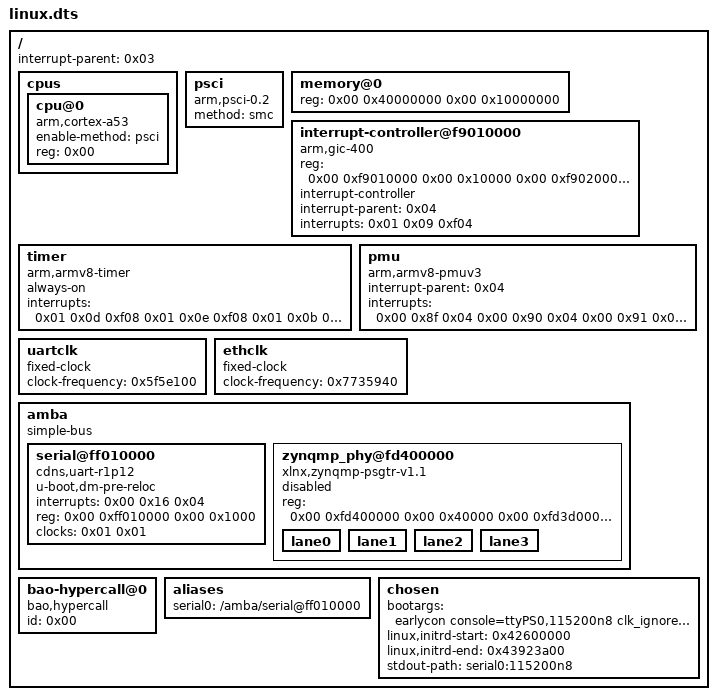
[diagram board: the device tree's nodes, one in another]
/dts-v1/;

/ {
	#address-cells = <0x02>;
	#size-cells = <0x02>;
	interrupt-parent = <0x03>;

	cpus {
		#size-cells = <0x00>;
		#address-cells = <0x01>;

		cpu@0 {
			compatible = "arm,cortex-a53\0arm,armv8";
			device_type = "cpu";
			enable-method = "psci";
			reg = <0x00>;
		};
	};

	psci {
		compatible = "arm,psci-0.2";
		method = "smc";
	};

	memory@0 {
		device_type = "memory";
		reg = <0x00 0x40000000 0x00 0x10000000>;
	};

	interrupt-controller@f9010000 {
		compatible = "arm,gic-400\0arm,cortex-a15-gic";
		#interrupt-cells = <0x03>;
		reg = <0x00 0xf9010000 0x00 0x10000 0x00 0xf9020000 0x00 0x20000 0x00 0xf9040000 0x00 0x20000 0x00 0xf9060000 0x00 0x20000>;
		interrupt-controller;
		interrupt-parent = <0x04>;
		interrupts = <0x01 0x09 0xf04>;
		phandle = <0x03>;
	};

	timer {
		compatible = "arm,armv8-timer";
		always-on;
		interrupts = <0x01 0x0d 0xf08 0x01 0x0e 0xf08 0x01 0x0b 0xf08 0x01 0x0a 0xf08>;
	};

	pmu {
		compatible = "arm,armv8-pmuv3";
		interrupt-parent = <0x04>;
		interrupts = <0x00 0x8f 0x04 0x00 0x90 0x04 0x00 0x91 0x04 0x00 0x92 0x04>;
	};

	uartclk {
		compatible = "fixed-clock";
		#clock-cells = <0x00>;
		clock-frequency = <0x5f5e100>;
		phandle = <0x01>;
	};

	ethclk {
		compatible = "fixed-clock";
		#clock-cells = <0x00>;
		clock-frequency = <0x7735940>;
		phandle = <0x02>;
	};

	amba {
		compatible = "simple-bus";
		#address-cells = <0x02>;
		#size-cells = <0x02>;
		ranges;

		serial@ff010000 {
			u-boot,dm-pre-reloc;
			compatible = "cdns,uart-r1p12\0xlnx,xuartps";
			status = "okay";
			interrupts = <0x00 0x16 0x04>;
			reg = <0x00 0xff010000 0x00 0x1000>;
			clock-names = "uart_clk\0pclk";
			clocks = <0x01 0x01>;
		};

		zynqmp_phy@fd400000 {
			compatible = "xlnx,zynqmp-psgtr-v1.1";
			status = "disabled";
			reg = <0x00 0xfd400000 0x00 0x40000 0x00 0xfd3d0000 0x00 0x1000>;
			reg-names = "serdes\0siou";

			lane0 {
				#phy-cells = <0x04>;
			};

			lane1 {
				#phy-cells = <0x04>;
			};

			lane2 {
				#phy-cells = <0x04>;
			};

			lane3 {
				#phy-cells = <0x04>;
			};
		};
	};

	bao-hypercall@0 {
		compatible = "bao,hypercall";
		id = <0x00>;
	};

	aliases {
		serial0 = "/amba/serial@ff010000";
	};

	chosen {
		bootargs = "earlycon console=ttyPS0,115200n8 clk_ignore_unused carrier_timeout=0 root=/dev/ram0";
		linux,initrd-start = <0x42600000>;
		linux,initrd-end = <0x43923a00>;
		stdout-path = "serial0:115200n8";
	};
};
